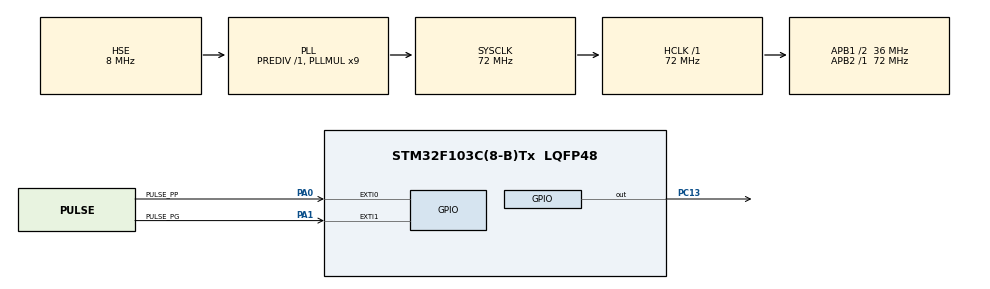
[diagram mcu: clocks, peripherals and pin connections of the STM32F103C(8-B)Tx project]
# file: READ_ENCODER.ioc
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Mcu.Family=STM32F1
Mcu.Name=STM32F103C(8-B)Tx
Mcu.Package=LQFP48
NVIC.EXTI0_IRQn=true\:0\:0\:false\:false\:true\:true\:true\:true
NVIC.EXTI1_IRQn=true\:0\:0\:false\:false\:true\:true\:true\:true
NVIC.PriorityGroup=NVIC_PRIORITYGROUP_4
PA0-WKUP.GPIO_Label=PULSE_PP
PA0-WKUP.GPIO_ModeDefaultEXTI=GPIO_MODE_IT_FALLING
PA0-WKUP.GPIO_PuPd=GPIO_PULLUP
PA0-WKUP.Signal=GPXTI0
PA1.GPIO_Label=PULSE_PG
PA1.GPIO_ModeDefaultEXTI=GPIO_MODE_IT_FALLING
PA1.GPIO_PuPd=GPIO_PULLUP
PA1.Signal=GPXTI1
PA13.Mode=Serial_Wire
PA13.Signal=SYS_JTMS-SWDIO
PA14.Mode=Serial_Wire
PA14.Signal=SYS_JTCK-SWCLK
PC13-TAMPER-RTC.Signal=GPIO_Output
PC14-OSC32_IN.Mode=LSE-External-Oscillator
PC14-OSC32_IN.Signal=RCC_OSC32_IN
PC15-OSC32_OUT.Mode=LSE-External-Oscillator
PC15-OSC32_OUT.Signal=RCC_OSC32_OUT
PD0-OSC_IN.Mode=HSE-External-Oscillator
PD0-OSC_IN.Signal=RCC_OSC_IN
PD1-OSC_OUT.Mode=HSE-External-Oscillator
PD1-OSC_OUT.Signal=RCC_OSC_OUT
ProjectManager.HeapSize=0x200
ProjectManager.StackSize=0x400
ProjectManager.TargetToolchain=STM32CubeIDE
RCC.AHBFreq_Value=72000000
RCC.APB1CLKDivider=RCC_HCLK_DIV2
RCC.APB1Freq_Value=36000000
RCC.APB1TimFreq_Value=72000000
RCC.APB2Freq_Value=72000000
RCC.APB2TimFreq_Value=72000000
RCC.HCLKFreq_Value=72000000
RCC.PLLMUL=RCC_PLL_MUL9
RCC.PLLSourceVirtual=RCC_PLLSOURCE_HSE
RCC.SYSCLKFreq_VALUE=72000000
RCC.SYSCLKSource=RCC_SYSCLKSOURCE_PLLCLK
RCC.USBFreq_Value=72000000
VP_TIM2_VS_ClockSourceINT.Mode=Internal
board=custom

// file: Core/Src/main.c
/* USER CODE BEGIN Header */
/**
 ******************************************************************************
 * @file           : main.c
 * @brief          : Main program body
 ******************************************************************************
 * @attention
 *
 * Copyright (c) 2024 STMicroelectronics.
 * All rights reserved.
 *
 * This software is licensed under terms that can be found in the LICENSE file
 * in the root directory of this software component.
 * If no LICENSE file comes with this software, it is provided AS-IS.
 *
 ******************************************************************************
 */
/* USER CODE END Header */
#include "main.h"

/* USER CODE BEGIN PD */
volatile short pulse_count_0 = 0;
volatile short pulse_count_1 = 0;
/* USER CODE END PD */

TIM_HandleTypeDef htim2;

/* USER CODE BEGIN PV */

void HAL_GPIO_EXTI_Callback(uint16_t GPIO_Pin)
{
	if(GPIO_Pin ==  GPIO_PIN_0)
		pulse_count_0++;
	else if(GPIO_Pin ==  GPIO_PIN_1)
		pulse_count_1++;
	else;
}

/* USER CODE END PV */

void SystemClock_Config(void);
static void MX_GPIO_Init(void);
static void MX_TIM2_Init(void);

int main(void)
{

	/* MCU Configuration--------------------------------------------------------*/

	/* Reset of all peripherals, Initializes the Flash interface and the Systick. */
	HAL_Init();

	/* Configure the system clock */
	SystemClock_Config();

	/* Initialize all configured peripherals */
	MX_GPIO_Init();
	MX_TIM2_Init();

	/* Infinite loop */
	while (1)
	{

		/* USER CODE BEGIN 3 */

//		if(pulse_count_0 % 10 == 0)
//		{
//			HAL_GPIO_TogglePin(GPIOC, GPIO_PIN_13);
//		}
//		else if(pulse_count_1 % 10 == 0)
//		{
//			HAL_GPIO_TogglePin(GPIOC, GPIO_PIN_13);
//		}else;
	}
	/* USER CODE END 3 */
}

void SystemClock_Config(void)
{
	RCC_OscInitTypeDef RCC_OscInitStruct = {0};
	RCC_ClkInitTypeDef RCC_ClkInitStruct = {0};

	/** Initializes the RCC Oscillators according to the specified parameters
	 * in the RCC_OscInitTypeDef structure.
	 */
	RCC_OscInitStruct.OscillatorType = RCC_OSCILLATORTYPE_HSE;
	RCC_OscInitStruct.HSEState = RCC_HSE_ON;
	RCC_OscInitStruct.HSEPredivValue = RCC_HSE_PREDIV_DIV1;
	RCC_OscInitStruct.HSIState = RCC_HSI_ON;
	RCC_OscInitStruct.PLL.PLLState = RCC_PLL_ON;
	RCC_OscInitStruct.PLL.PLLSource = RCC_PLLSOURCE_HSE;
	RCC_OscInitStruct.PLL.PLLMUL = RCC_PLL_MUL9;
	if (HAL_RCC_OscConfig(&RCC_OscInitStruct) != HAL_OK)
	{
		Error_Handler();
	}

	/** Initializes the CPU, AHB and APB buses clocks
	 */
	RCC_ClkInitStruct.ClockType = RCC_CLOCKTYPE_HCLK|RCC_CLOCKTYPE_SYSCLK
			|RCC_CLOCKTYPE_PCLK1|RCC_CLOCKTYPE_PCLK2;
	RCC_ClkInitStruct.SYSCLKSource = RCC_SYSCLKSOURCE_PLLCLK;
	RCC_ClkInitStruct.AHBCLKDivider = RCC_SYSCLK_DIV1;
	RCC_ClkInitStruct.APB1CLKDivider = RCC_HCLK_DIV2;
	RCC_ClkInitStruct.APB2CLKDivider = RCC_HCLK_DIV1;

	if (HAL_RCC_ClockConfig(&RCC_ClkInitStruct, FLASH_LATENCY_2) != HAL_OK)
	{
		Error_Handler();
	}
}

static void MX_TIM2_Init(void)
{

	TIM_ClockConfigTypeDef sClockSourceConfig = {0};
	TIM_MasterConfigTypeDef sMasterConfig = {0};

	htim2.Instance = TIM2;
	htim2.Init.Prescaler = 0;
	htim2.Init.CounterMode = TIM_COUNTERMODE_UP;
	htim2.Init.Period = 65535;
	htim2.Init.ClockDivision = TIM_CLOCKDIVISION_DIV1;
	htim2.Init.AutoReloadPreload = TIM_AUTORELOAD_PRELOAD_DISABLE;
	if (HAL_TIM_Base_Init(&htim2) != HAL_OK)
	{
		Error_Handler();
	}
	sClockSourceConfig.ClockSource = TIM_CLOCKSOURCE_INTERNAL;
	if (HAL_TIM_ConfigClockSource(&htim2, &sClockSourceConfig) != HAL_OK)
	{
		Error_Handler();
	}
	sMasterConfig.MasterOutputTrigger = TIM_TRGO_RESET;
	sMasterConfig.MasterSlaveMode = TIM_MASTERSLAVEMODE_DISABLE;
	if (HAL_TIMEx_MasterConfigSynchronization(&htim2, &sMasterConfig) != HAL_OK)
	{
		Error_Handler();
	}

}

static void MX_GPIO_Init(void)
{
	GPIO_InitTypeDef GPIO_InitStruct = {0};

	/* GPIO Ports Clock Enable */
	__HAL_RCC_GPIOC_CLK_ENABLE();
	__HAL_RCC_GPIOD_CLK_ENABLE();
	__HAL_RCC_GPIOA_CLK_ENABLE();

	/*Configure GPIO pin Output Level */
	HAL_GPIO_WritePin(GPIOC, GPIO_PIN_13, GPIO_PIN_RESET);

	/*Configure GPIO pin : PC13 */
	GPIO_InitStruct.Pin = GPIO_PIN_13;
	GPIO_InitStruct.Mode = GPIO_MODE_OUTPUT_PP;
	GPIO_InitStruct.Pull = GPIO_NOPULL;
	GPIO_InitStruct.Speed = GPIO_SPEED_FREQ_LOW;
	HAL_GPIO_Init(GPIOC, &GPIO_InitStruct);

	/*Configure GPIO pins : PULSE_PP_Pin PULSE_PG_Pin */
	GPIO_InitStruct.Pin = PULSE_PP_Pin|PULSE_PG_Pin;
	GPIO_InitStruct.Mode = GPIO_MODE_IT_FALLING;
	GPIO_InitStruct.Pull = GPIO_PULLUP;
	HAL_GPIO_Init(GPIOA, &GPIO_InitStruct);

	/* EXTI interrupt init*/
	HAL_NVIC_SetPriority(EXTI0_IRQn, 0, 0);
	HAL_NVIC_EnableIRQ(EXTI0_IRQn);

	HAL_NVIC_SetPriority(EXTI1_IRQn, 0, 0);
	HAL_NVIC_EnableIRQ(EXTI1_IRQn);

}

void Error_Handler(void)
{
	__disable_irq();
	while (1)
	{
	}
}
